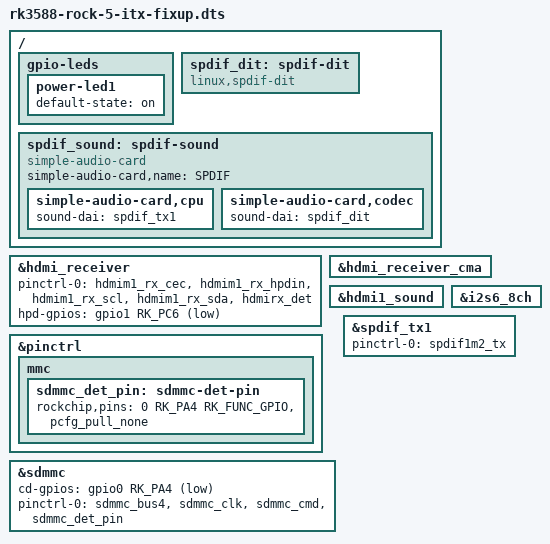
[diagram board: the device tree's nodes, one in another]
// SPDX-License-Identifier: (GPL-2.0+ OR MIT)

#include "rk3588-rock-5-itx.dts"

// 6cb4ec63ba9a arm64: dts: rockchip: configure hdmirx in Rock 5 ITX (from linux kernel archives)
// https://github.com/torvalds/linux/commit/6cb4ec63ba9a5831621cf951b7af55c67beeb97b
// First released in: NOT YET in googlesource (linux kernel archives only, kernel 6.19)

&hdmi_receiver {
	pinctrl-0 = <&hdmim1_rx_cec &hdmim1_rx_hpdin &hdmim1_rx_scl &hdmim1_rx_sda &hdmirx_det>;
	pinctrl-names = "default";
	hpd-gpios = <&gpio1 RK_PC6 GPIO_ACTIVE_LOW>;
	status = "okay";
};

&hdmi_receiver_cma {
	status = "okay";
};

// c3f1daa78e arm64: dts: rockchip: enable HDMI audio on Rock 5 ITX
// https://git.kernel.org/pub/scm/linux/kernel/git/devicetree/devicetree-rebasing.git/commit/?id=c3f1daa78e
// First released in: v6.19-dts

&hdmi1_sound {
	status = "okay";
};

&i2s6_8ch {
	status = "okay";
};

// 809b1a4533 arm64: dts: rockchip: Use default-state for power LED for Radxa boards
// https://git.kernel.org/pub/scm/linux/kernel/git/devicetree/devicetree-rebasing.git/commit/?id=809b1a4533
// First released in: v6.19-dts

/ {
	gpio-leds {
		power-led1 {
			default-state = "on";
		};
	};
};

// f37dc939fe arm64: dts: rockchip: Switch microSD card detect to gpio on Radxa ROCK 5 ITX/5C
// https://git.kernel.org/pub/scm/linux/kernel/git/devicetree/devicetree-rebasing.git/commit/?id=f37dc939fe
// First released in: v6.19-dts

&pinctrl {
	mmc {
		sdmmc_det_pin: sdmmc-det-pin {
			rockchip,pins = <0 RK_PA4 RK_FUNC_GPIO &pcfg_pull_none>;
		};
	};
};

&sdmmc {
	cd-gpios = <&gpio0 RK_PA4 GPIO_ACTIVE_LOW>;
	pinctrl-0 = <&sdmmc_bus4 &sdmmc_clk &sdmmc_cmd &sdmmc_det_pin>;
	/delete-property/ max-frequency;
};

// 7a509b4cc0 arm64: dts: rockchip: Enable SPDIF audio on Rock 5 ITX
// https://git.kernel.org/pub/scm/linux/kernel/git/devicetree/devicetree-rebasing.git/commit/?id=7a509b4cc0
// First released in: v7.0-dts

/ {
	spdif_dit: spdif-dit {
		compatible = "linux,spdif-dit";
		#sound-dai-cells = <0>;
	};

	spdif_sound: spdif-sound {
		compatible = "simple-audio-card";
		simple-audio-card,name = "SPDIF";

		simple-audio-card,cpu {
			sound-dai = <&spdif_tx1>;
		};

		simple-audio-card,codec {
			sound-dai = <&spdif_dit>;
		};
	};
};

&spdif_tx1 {
	pinctrl-0 = <&spdif1m2_tx>;
	status = "okay";
};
